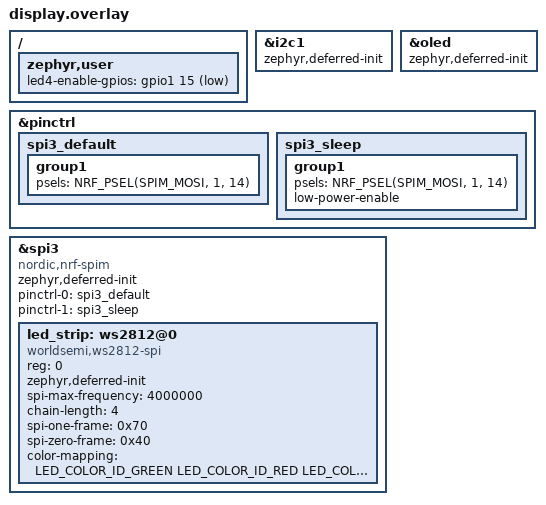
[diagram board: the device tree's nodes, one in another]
#include <dt-bindings/led/led.h>
&i2c1 { zephyr,deferred-init; };
&oled { zephyr,deferred-init; };
/ { zephyr,user { led4-enable-gpios = <&gpio1 15 GPIO_ACTIVE_LOW>; }; };
&pinctrl {
	spi3_default: spi3_default {
		group1 {
			psels = <NRF_PSEL(SPIM_MOSI, 1, 14)>;
		};
	};

	spi3_sleep: spi3_sleep {
		group1 {
			psels = <NRF_PSEL(SPIM_MOSI, 1, 14)>;
			low-power-enable;
		};
	};
};

&spi3 {
	compatible = "nordic,nrf-spim";
	status = "okay";
    zephyr,deferred-init;

	pinctrl-0 = <&spi3_default>;
	pinctrl-1 = <&spi3_sleep>;
	pinctrl-names = "default", "sleep";

	led_strip: ws2812@0 {
		compatible = "worldsemi,ws2812-spi";
		reg = <0>;
        zephyr,deferred-init;
		spi-max-frequency = <4000000>; // 4MHz = 0.25us

		chain-length = <4>; /* number of LEDs */
		spi-one-frame = <0x70>; // 01110000 -> T1H = 0.25 * 3 = 0.75us
		spi-zero-frame = <0x40>; // 01000000 -> T0H = 0.25us
		color-mapping = <LED_COLOR_ID_GREEN
				 LED_COLOR_ID_RED
				 LED_COLOR_ID_BLUE>;
	};
};
